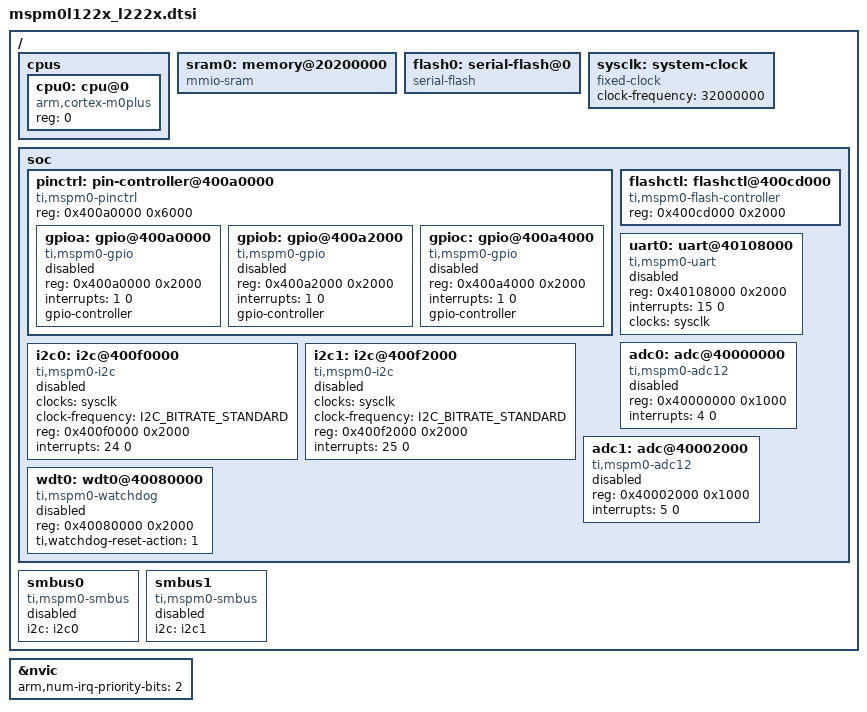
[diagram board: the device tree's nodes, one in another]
/* SPDX-License-Identifier: Apache-2.0 */

#include <arm/armv6-m.dtsi>
#include <zephyr/dt-bindings/gpio/gpio.h>
#include <zephyr/dt-bindings/i2c/i2c.h>
#include <zephyr/dt-bindings/adc/adc.h>
#include <zephyr/dt-bindings/adc/mspm0_adc.h>

/ {

	cpus {
		#address-cells = <1>;
		#size-cells = <0>;

		cpu0: cpu@0 {
			compatible = "arm,cortex-m0plus";
			reg = <0>;
		};
	};

	sram0: memory@20200000 {
		compatible = "mmio-sram";
	};

	flash0: serial-flash@0 {
		compatible = "serial-flash";
	};

	sysclk: system-clock {
		compatible = "fixed-clock";
		clock-frequency = <32000000>;
		#clock-cells = <0>;
	};

	soc {

		pinctrl: pin-controller@400a0000{
			compatible = "ti,mspm0-pinctrl";
			#address-cells = <1>;
			#size-cells = <1>;
			reg = <0x400a0000 0x6000>;

			gpioa: gpio@400a0000 {
				compatible = "ti,mspm0-gpio";
				reg = <0x400a0000 0x2000>;
				interrupts = <1 0>;
				status = "disabled";
				gpio-controller;
				#gpio-cells = <2>;
			};

			gpiob: gpio@400a2000 {
				compatible = "ti,mspm0-gpio";
				reg = <0x400a2000 0x2000>;
				interrupts = <1 0>;
				status = "disabled";
				gpio-controller;
				#gpio-cells = <2>;
			};

			gpioc: gpio@400a4000 {
				compatible = "ti,mspm0-gpio";
				reg = <0x400a4000 0x2000>;
				interrupts = <1 0>;
				status = "disabled";
				gpio-controller;
				#gpio-cells = <2>;
			};

		};

		flashctl: flashctl@400cd000{
			compatible = "ti,mspm0-flash-controller";
			reg = <0x400cd000 0x2000>;
			status = "okay";

			#address-cells = <1>;
			#size-cells = <1>;
		};

		uart0: uart@40108000 {
			compatible = "ti,mspm0-uart";
			reg = <0x40108000 0x2000>;
			interrupts = <15 0>;
			clocks = <&sysclk>;
			status = "disabled";
		};

		i2c0: i2c@400f0000 {
			compatible = "ti,mspm0-i2c";
			clocks = <&sysclk>;
			clock-frequency = <I2C_BITRATE_STANDARD>;
			#address-cells = <1>;
			#size-cells = <0>;
			reg = <0x400f0000 0x2000>;
			interrupts = <24 0>;
			status = "disabled";
		};

		i2c1: i2c@400f2000 {
			compatible = "ti,mspm0-i2c";
			clocks = <&sysclk>;
			clock-frequency = <I2C_BITRATE_STANDARD>;
			#address-cells = <1>;
			#size-cells = <0>;
			reg = <0x400f2000 0x2000>;
			interrupts = <25 0>;
			status = "disabled";
		};

		adc0: adc@40000000 {
			compatible = "ti,mspm0-adc12";
			reg = <0x40000000 0x1000>;
			interrupts = <4 0>;
			status = "disabled";
			#io-channel-cells = <1>;
		};

		adc1: adc@40002000 {
			compatible = "ti,mspm0-adc12";
			reg = <0x40002000 0x1000>;
			interrupts = <5 0>;
			status = "disabled";
			#io-channel-cells = <1>;
		};

		wdt0: wdt0@40080000 {
			compatible = "ti,mspm0-watchdog";
			reg = <0x40080000 0x2000>;
			status = "disabled";
			ti,watchdog-reset-action = <1>;
		};
	};

	smbus0: smbus0 {
		compatible = "ti,mspm0-smbus";
		i2c = <&i2c0>;
		status = "disabled";
	};

	smbus1: smbus1 {
		compatible = "ti,mspm0-smbus";
		i2c = <&i2c1>;
		status = "disabled";
	};
};

&nvic {
	arm,num-irq-priority-bits = <2>;
};
